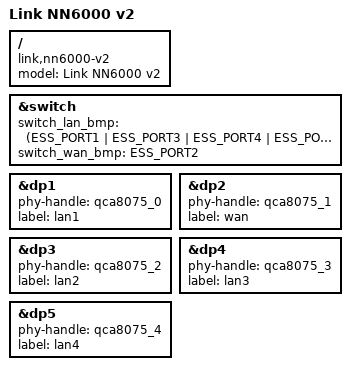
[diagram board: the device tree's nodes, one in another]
// SPDX-License-Identifier: GPL-2.0-or-later OR MIT
//
// 连我 NN6000 V2 (Link NN6000 v2)：四 LAN + WAN
// 适配基底: immortalwrt openwrt-25.12；来源: immortalwrt master 的 ipq6000-nn6000-v2.dts

/dts-v1/;

#include "ipq6000-link.dtsi"

/ {
	model = "Link NN6000 v2";
	compatible = "link,nn6000-v2", "qcom,ipq6018";
};

&switch {
	switch_lan_bmp = <(ESS_PORT1 | ESS_PORT3 | ESS_PORT4 | ESS_PORT5)>;
	switch_wan_bmp = <ESS_PORT2>;
};

&dp1 {
	status = "okay";
	phy-handle = <&qca8075_0>;
	label = "lan1";
};

&dp2 {
	status = "okay";
	phy-handle = <&qca8075_1>;
	label = "wan";
};

&dp3 {
	status = "okay";
	phy-handle = <&qca8075_2>;
	label = "lan2";
};

&dp4 {
	status = "okay";
	phy-handle = <&qca8075_3>;
	label = "lan3";
};

&dp5 {
	status = "okay";
	phy-handle = <&qca8075_4>;
	label = "lan4";
};
